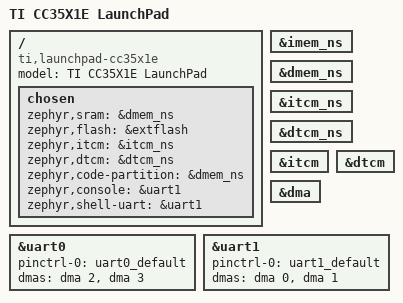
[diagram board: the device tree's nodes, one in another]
/*
 * Copyright (c) 2025 Conclusive Engineering Sp. z o.o.
 *
 * SPDX-License-Identifier: Apache-2.0
 */

/dts-v1/;

#include <ti/cc35xxe.dtsi>
#include "lp_em_cc35x1-pinctrl.dtsi"

/ {
	model = "TI CC35X1E LaunchPad";
	compatible = "ti,launchpad-cc35x1e";

	chosen {
		zephyr,sram = &dmem_ns;
		zephyr,flash = &extflash;
		zephyr,itcm = &itcm_ns;
		zephyr,dtcm = &dtcm_ns;
		zephyr,code-partition = &dmem_ns;
		zephyr,console = &uart1;
		zephyr,shell-uart = &uart1;
	};

};

&imem_ns {
	status = "okay";
};

&dmem_ns {
	status = "okay";
};

&itcm_ns {
	status = "okay";
};

&dtcm_ns {
	status = "okay";
};

&itcm {
	status = "okay";
};

&dtcm {
	status = "okay";
};

&dma {
	status = "okay";
};

&uart0 {
	status = "okay";
	pinctrl-0 = <&uart0_default>;
	pinctrl-names = "default";
	dmas = <&dma 2>, <&dma 3>;
	dma-names = "tx", "rx";
};

&uart1 {
	status = "okay";
	pinctrl-0 = <&uart1_default>;
	pinctrl-names = "default";
	dmas = <&dma 0>, <&dma 1>;
	dma-names = "tx", "rx";
};
